AUTOSAR XML (schema 00050)
package /SoftwareComponents
  sensor actuator sw component type Engine_Speed
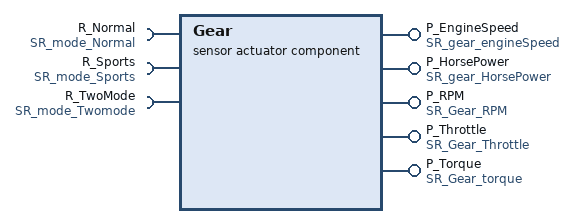
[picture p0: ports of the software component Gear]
  sensor actuator sw component type Gear
    5 x provide port:
      P_EngineSpeed: provided-interface=SR_gear_engineSpeed
      P_HorsePower: provided-interface=SR_gear_HorsePower
      P_RPM: provided-interface=SR_Gear_RPM
      P_Throttle: provided-interface=SR_Gear_Throttle
      P_Torque: provided-interface=SR_Gear_torque
    require port R_Normal: required-interface=SR_mode_Normal
    require port R_Sports: required-interface=SR_mode_Sports
    require port R_TwoMode: required-interface=SR_mode_Twomode
  sensor actuator sw component type HorsePower
    require port HorsePower: required-interface=SR_gear_HorsePower
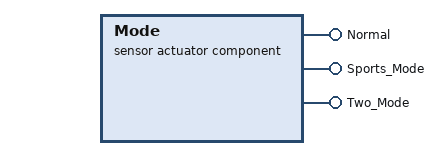
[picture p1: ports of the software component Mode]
  sensor actuator sw component type Mode
    provide port Normal
    provide port Sports_Mode
    provide port Two_Mode
  sensor actuator sw component type RPM
    require port RPM: required-interface=SR_Gear_RPM
  sensor actuator sw component type Throttle
    require port Throttle: required-interface=SR_Gear_Throttle
  sensor actuator sw component type Torque
    require port Torque: required-interface=SR_Gear_torque
package /port_interfaces
  12 x sender receiver interface:
    SR_Gear_RPM
    SR_Gear_Throttle
    SR_Gear_torque
    SR_Throttle_Enginespped
    SR_Throttle_RPM
    SR_Throttle_Torque
    SR_gear_HorsePower
    SR_gear_engineSpeed
    SR_mode_Normal
    SR_mode_Sports
    SR_mode_Twomode
    SR_throttle_HorsePower
